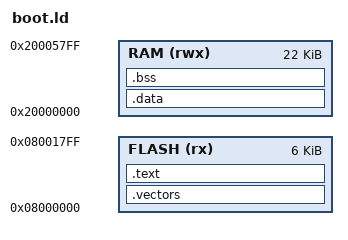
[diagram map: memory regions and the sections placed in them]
/* SPDX-License-Identifier: GPL-2.0-only */
ENTRY(Reset_Handler)
MEMORY {
    FLASH (rx) : ORIGIN = 0x08000000, LENGTH = 6K
    RAM (rwx) : ORIGIN = 0x20000000, LENGTH = 22K
}
_estack = ORIGIN(RAM) + LENGTH(RAM);
SECTIONS {
    .vectors : { KEEP(*(.vectors)) } > FLASH
    .text : { *(.text*) *(.rodata*) . = ALIGN(4); } > FLASH
    .data (NOLOAD) : { *(.data*) } > RAM
    ASSERT(SIZEOF(.data) == 0, "Bootloader startup requires all mutable state in BSS")
    .bss (NOLOAD) : { . = ALIGN(4); _sbss = .; *(.bss*) *(COMMON) . = ALIGN(4); _ebss = .; } > RAM
    /DISCARD/ : { *(.comment*) *(.ARM.exidx*) *(.ARM.extab*) }
}
